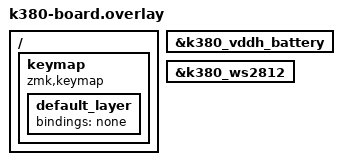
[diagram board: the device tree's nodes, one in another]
#include <behaviors.dtsi>

/ {
    keymap {
        compatible = "zmk,keymap";
        default_layer { bindings = <&none>; };
    };
};

&k380_vddh_battery {
    status = "okay";
};

&k380_ws2812 {
    status = "okay";
};
